VERSION ""

NS_ :

BS_:

BU_: ECU1 ECU2 ECU3 ECU4 ECU5 ECU6 ECU7 ECU8 ECU9 ECU10 ECU11 ECU12 ECU13

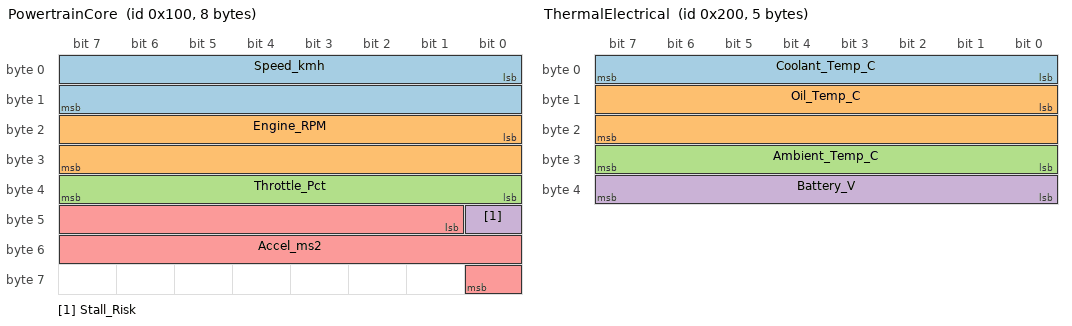
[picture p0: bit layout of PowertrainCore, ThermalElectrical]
BO_ 256 PowertrainCore: 8 ECU1
 SG_ Speed_kmh : 0|16@1+ (1,0) [0|300] "kmph" ECU1
 SG_ Engine_RPM : 16|16@1+ (1,0) [0|8000] "rpm" ECU1
 SG_ Throttle_Pct : 32|8@1+ (1,0) [0|100] "pct" ECU1
 SG_ Stall_Risk : 40|1@1+ (1,0) [0|1] "" ECU1
 SG_ Accel_ms2 : 41|16@1- (1,0) [-200|200] "ms2" ECU1

BO_ 512 ThermalElectrical: 5 ECU2
 SG_ Coolant_Temp_C : 0|8@1+ (1,0) [0|200] "degC" ECU2
 SG_ Oil_Temp_C : 8|16@1+ (1,0) [0|200] "degC" ECU2
 SG_ Ambient_Temp_C : 24|8@1+ (1,0) [0|200] "degC" ECU2
 SG_ Battery_V : 32|8@1+ (1,0) [0|20] "V" ECU2

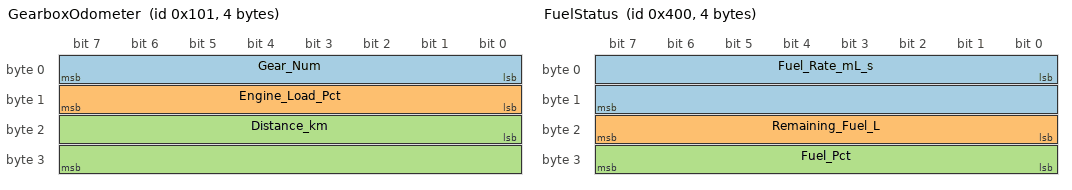
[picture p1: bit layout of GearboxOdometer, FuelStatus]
BO_ 257 GearboxOdometer: 4 ECU3
 SG_ Gear_Num : 0|8@1+ (1,0) [0|5] "" ECU3
 SG_ Engine_Load_Pct : 8|8@1+ (1,0) [0|100] "pct" ECU3
 SG_ Distance_km : 16|16@1+ (1,0) [0|999] "km" ECU3

BO_ 1024 FuelStatus: 4 ECU4
 SG_ Fuel_Rate_mL_s : 0|16@1+ (1,0) [0|100] "mLs" ECU4
 SG_ Remaining_Fuel_L : 16|8@1+ (1,0) [0|50] "L" ECU4
 SG_ Fuel_Pct : 24|8@1+ (1,0) [0|100] "pct" ECU4

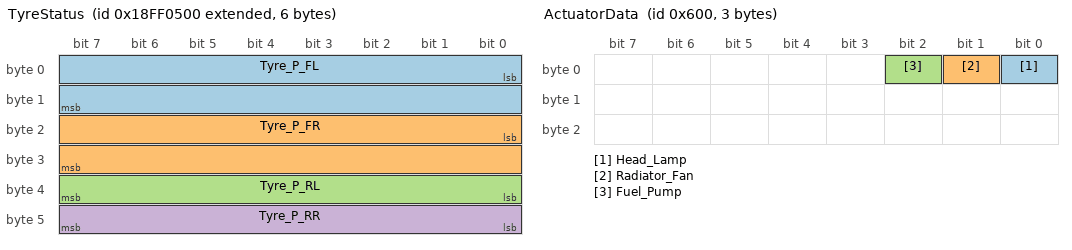
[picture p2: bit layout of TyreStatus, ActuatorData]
BO_ 2566849792 TyreStatus: 6 ECU5
 SG_ Tyre_P_FL : 0|16@1+ (1,0) [0|60] "psi" ECU5
 SG_ Tyre_P_FR : 16|16@1+ (1,0) [0|60] "psi" ECU5
 SG_ Tyre_P_RL : 32|8@1+ (1,0) [0|60] "psi" ECU5
 SG_ Tyre_P_RR : 40|8@1+ (1,0) [0|60] "psi" ECU5

BO_ 1536 ActuatorData: 3 ECU6
 SG_ Head_Lamp : 0|1@1+ (1,0) [0|1] "" ECU6
 SG_ Radiator_Fan : 1|1@1+ (1,0) [0|1] "" ECU6
 SG_ Fuel_Pump : 2|1@1+ (1,0) [0|1] "" ECU6

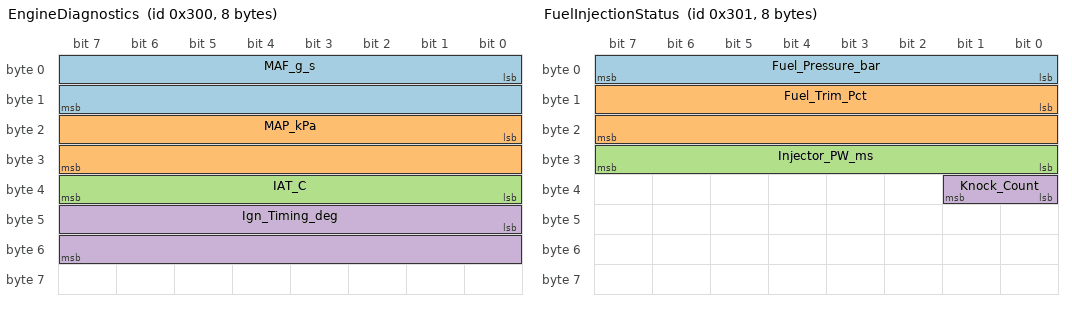
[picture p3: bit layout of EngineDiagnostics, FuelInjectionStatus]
BO_ 768 EngineDiagnostics: 8 ECU7
 SG_ MAF_g_s : 0|16@1+ (0.01,0) [0|100] "g/s" ECU7
 SG_ MAP_kPa : 16|16@1+ (0.1,0) [0|110] "kPa" ECU7
 SG_ IAT_C : 32|8@1- (1,0) [-40|125] "degC" ECU7
 SG_ Ign_Timing_deg : 40|16@1+ (0.1,0) [0|40] "deg" ECU7

BO_ 769 FuelInjectionStatus: 8 ECU8
 SG_ Fuel_Pressure_bar : 0|8@1+ (0.1,0) [0|5] "bar" ECU8
 SG_ Fuel_Trim_Pct : 8|16@1- (0.1,0) [-25|25] "pct" ECU8
 SG_ Injector_PW_ms : 24|8@1+ (0.1,0) [0|15] "ms" ECU8
 SG_ Knock_Count : 32|2@1+ (1,0) [0|2] "" ECU8

BO_ 770 EmissionsThermal: 4 ECU9
 SG_ Catalyst_Temp_C : 0|16@1+ (0.1,0) [0|900] "degC" ECU9
 SG_ Trans_Fluid_Temp_C : 16|16@1- (0.1,0) [-40|200] "degC" ECU9

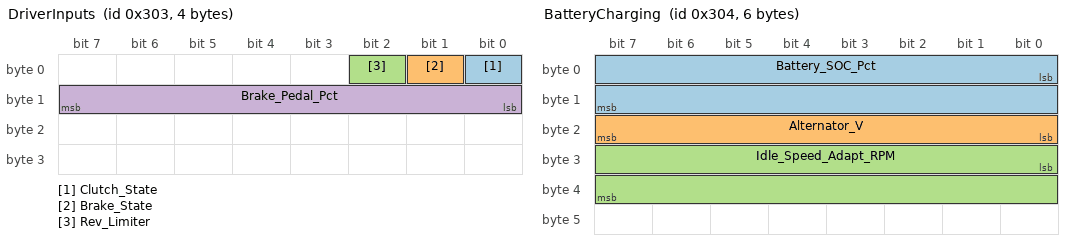
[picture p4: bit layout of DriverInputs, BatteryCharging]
BO_ 771 DriverInputs: 4 ECU10
 SG_ Clutch_State : 0|1@1+ (1,0) [0|1] "" ECU10
 SG_ Brake_State : 1|1@1+ (1,0) [0|1] "" ECU10
 SG_ Rev_Limiter : 2|1@1+ (1,0) [0|1] "" ECU10
 SG_ Brake_Pedal_Pct : 8|8@1+ (1,0) [0|100] "pct" ECU10

BO_ 772 BatteryCharging: 6 ECU11
 SG_ Battery_SOC_Pct : 0|16@1+ (0.1,0) [0|100] "pct" ECU11
 SG_ Alternator_V : 16|8@1+ (0.1,0) [0|15] "V" ECU11
 SG_ Idle_Speed_Adapt_RPM : 24|16@1+ (1,0) [500|1500] "rpm" ECU11

BO_ 773 UDSStatus: 1 ECU12
 SG_ UDS_Session : 0|8@1+ (1,0) [0|3] "" ECU12

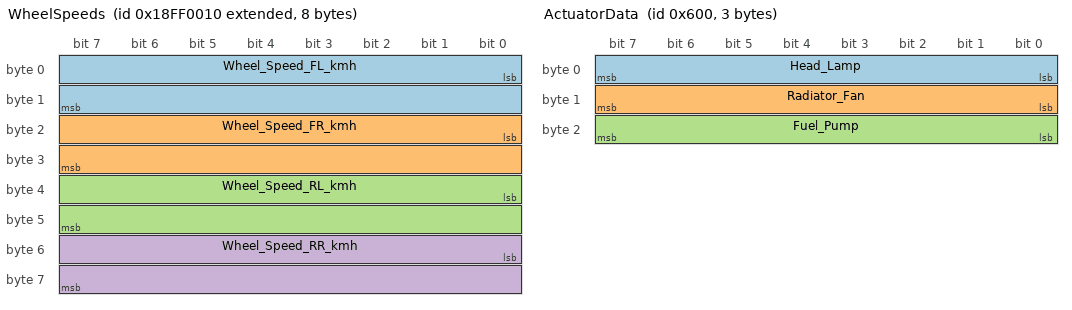
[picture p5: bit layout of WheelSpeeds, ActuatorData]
BO_ 2566848528 WheelSpeeds: 8 ECU13
 SG_ Wheel_Speed_FL_kmh : 0|16@1+ (1,0) [0|300] "kmph" ECU13
 SG_ Wheel_Speed_FR_kmh : 16|16@1+ (1,0) [0|300] "kmph" ECU13
 SG_ Wheel_Speed_RL_kmh : 32|16@1+ (1,0) [0|300] "kmph" ECU13
 SG_ Wheel_Speed_RR_kmh : 48|16@1+ (1,0) [0|300] "kmph" ECU13

BO_ 1536 ActuatorData: 3 ECU8
 SG_ Head_Lamp     : 0|8@1+  (1,0) [0|1] "" ECU8
 SG_ Radiator_Fan  : 8|8@1+  (1,0) [0|1] "" ECU8
 SG_ Fuel_Pump     : 16|8@1+ (1,0) [0|1] "" ECU8

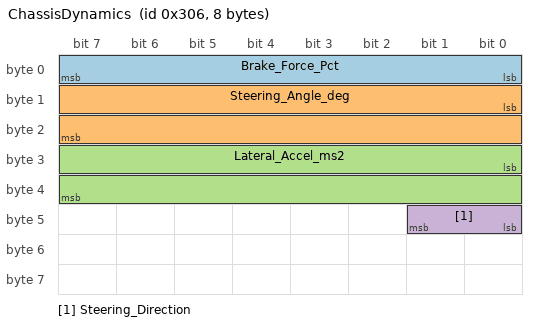
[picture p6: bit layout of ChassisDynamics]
BO_ 774 ChassisDynamics: 8 ECU13
 SG_ Brake_Force_Pct      : 0|8@1+   (0.5,0)   [0|100]   "%"      ECU13
 SG_ Steering_Angle_deg   : 8|16@1-  (0.1,0)   [-45|45]  "deg"    ECU13
 SG_ Lateral_Accel_ms2    : 24|16@1- (0.01,0)  [-20|20]  "m/s2"   ECU13
 SG_ Steering_Direction   : 40|2@1+  (1,0)     [0|2]     ""       ECU13
